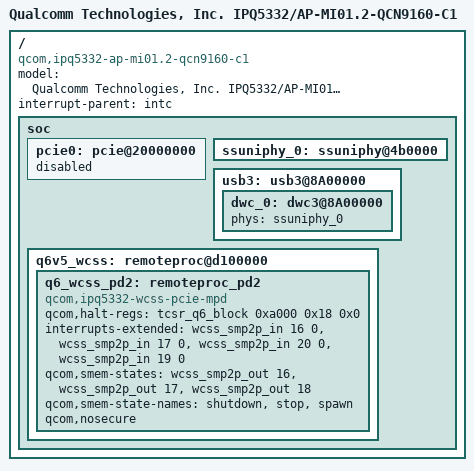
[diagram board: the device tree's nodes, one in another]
// SPDX-License-Identifier: (GPL-2.0+ OR BSD-3-Clause)
/*
 * IPQ5332 AP-MI01.2-QCN9160-C1 board device tree source
 *
 * Copyright (c) 2020-2021 The Linux Foundation. All rights reserved.
 * Copyright (c) 2022 Qualcomm Innovation Center, Inc. All rights reserved.
 */

/dts-v1/;

#include "ipq5332-mi01.2.dts"


/ {
	#address-cells = <0x2>;
	#size-cells = <0x2>;
	model = "Qualcomm Technologies, Inc. IPQ5332/AP-MI01.2-QCN9160-C1";
	compatible = "qcom,ipq5332-ap-mi01.2-qcn9160-c1", "qcom,ipq5332";
	interrupt-parent = <&intc>;

	soc {
		pcie0: pcie@20000000 {
			status = "disabled";
		};

		ssuniphy_0: ssuniphy@4b0000 {
			status = "ok";
		};

		usb3: usb3@8A00000 {
			dwc_0: dwc3@8A00000 {
				#phy-cells = <0>;
				phys = <&ssuniphy_0>;
				phy-names = "usb3-phy";
			};
		};

		q6v5_wcss: remoteproc@d100000 {
			q6_wcss_pd2: remoteproc_pd2 {
				compatible = "qcom,ipq5332-wcss-pcie-mpd";
				qcom,halt-regs = <&tcsr_q6_block 0xa000 0x18 0x0>;
				interrupts-extended = <&wcss_smp2p_in 16 0>,
							<&wcss_smp2p_in 17 0>,
							<&wcss_smp2p_in 20 0>,
							<&wcss_smp2p_in 19 0>;
				interrupt-names = "fatal",
						"ready",
						"spawn-ack",
						"stop-ack";

				qcom,smem-states = <&wcss_smp2p_out 16>,
						<&wcss_smp2p_out 17>,
						<&wcss_smp2p_out 18>;
				qcom,smem-state-names = "shutdown",
							"stop",
							"spawn";
				qcom,nosecure;
			};
		};
	};
};
